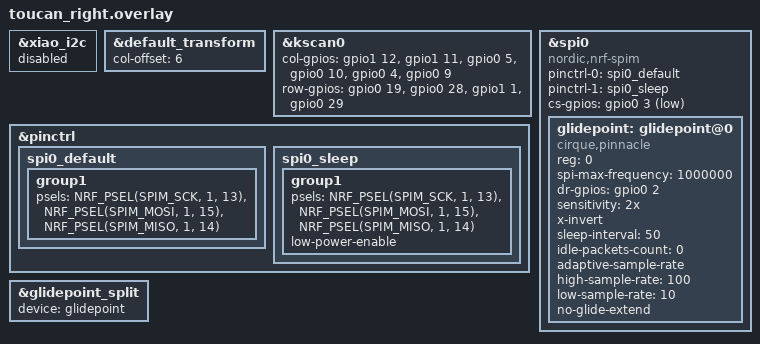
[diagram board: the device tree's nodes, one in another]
#include "toucan.dtsi"
#include <input/processors.dtsi>
#include <dt-bindings/zmk/input_transform.h>

&xiao_i2c {
    status = "disabled";
};

&default_transform {
    col-offset = <6>;
};

&kscan0 {
    col-gpios
    = <&gpio1 12 GPIO_ACTIVE_HIGH>
    , <&gpio1 11 GPIO_ACTIVE_HIGH>
    , <&gpio0 5 GPIO_ACTIVE_HIGH>
    , <&gpio0 10 GPIO_ACTIVE_HIGH>
    , <&gpio0 4 GPIO_ACTIVE_HIGH>
    , <&gpio0 9 GPIO_ACTIVE_HIGH>
    ;

    row-gpios
    = <&gpio0 19 (GPIO_ACTIVE_HIGH | GPIO_PULL_DOWN)>
    , <&gpio0 28 (GPIO_ACTIVE_HIGH | GPIO_PULL_DOWN)>
    , <&gpio1 1 (GPIO_ACTIVE_HIGH | GPIO_PULL_DOWN)>
    , <&gpio0 29 (GPIO_ACTIVE_HIGH | GPIO_PULL_DOWN)>
    ;
};

&pinctrl {
    spi0_default: spi0_default {
        group1 {
            psels = <NRF_PSEL(SPIM_SCK, 1, 13)>,
                <NRF_PSEL(SPIM_MOSI, 1, 15)>,
                <NRF_PSEL(SPIM_MISO, 1, 14)>;
        };
    };

     spi0_sleep: spi0_sleep {
        group1 {
            psels = <NRF_PSEL(SPIM_SCK, 1, 13)>,
                    <NRF_PSEL(SPIM_MOSI, 1, 15)>,
                    <NRF_PSEL(SPIM_MISO, 1, 14)>;
            low-power-enable;
        };
    };

};

&spi0 {
   compatible = "nordic,nrf-spim";
   status = "okay";
   pinctrl-0 = <&spi0_default>;
   pinctrl-1 = <&spi0_sleep>;
   pinctrl-names = "default", "sleep";
   cs-gpios = <&gpio0 3 GPIO_ACTIVE_LOW>;
   glidepoint:  glidepoint@0 {
        compatible = "cirque,pinnacle";
        reg = <0>;
        spi-max-frequency = <1000000>;
        status = "okay";
        dr-gpios = <&gpio0 2 (GPIO_ACTIVE_HIGH)>;
        sensitivity = "2x";
        x-invert;

        // Power optimization
        sleep-interval = <50>;       // Hardware-Sleep Scan-Intervall (Register 0x0C, default 50)
        idle-packets-count = <0>;    // Keine Z=0 Pakete nach Finger-Lift (spart MCU-Wakeups)

        // Adaptive Abtastrate — 100Hz bei Bewegung, 10Hz bei Stillstand
        adaptive-sample-rate;
        high-sample-rate = <100>;
        low-sample-rate = <10>;

        // GlideExtend deaktivieren (Cursor-Nachgleiten nach Finger-Lift)
        // Spart ~15% aktiv-Strom, stoppt Cursor sofort bei Finger-Lift
        no-glide-extend;
    };
};

&glidepoint_split {
    device = <&glidepoint>;

    // Optional
    // input-processors = <&zip_xy_transform (INPUT_TRANSFORM_XY_SWAP | INPUT_TRANSFORM_X_INVERT | INPUT_TRANSFORM_Y_INVERT)>;
};
